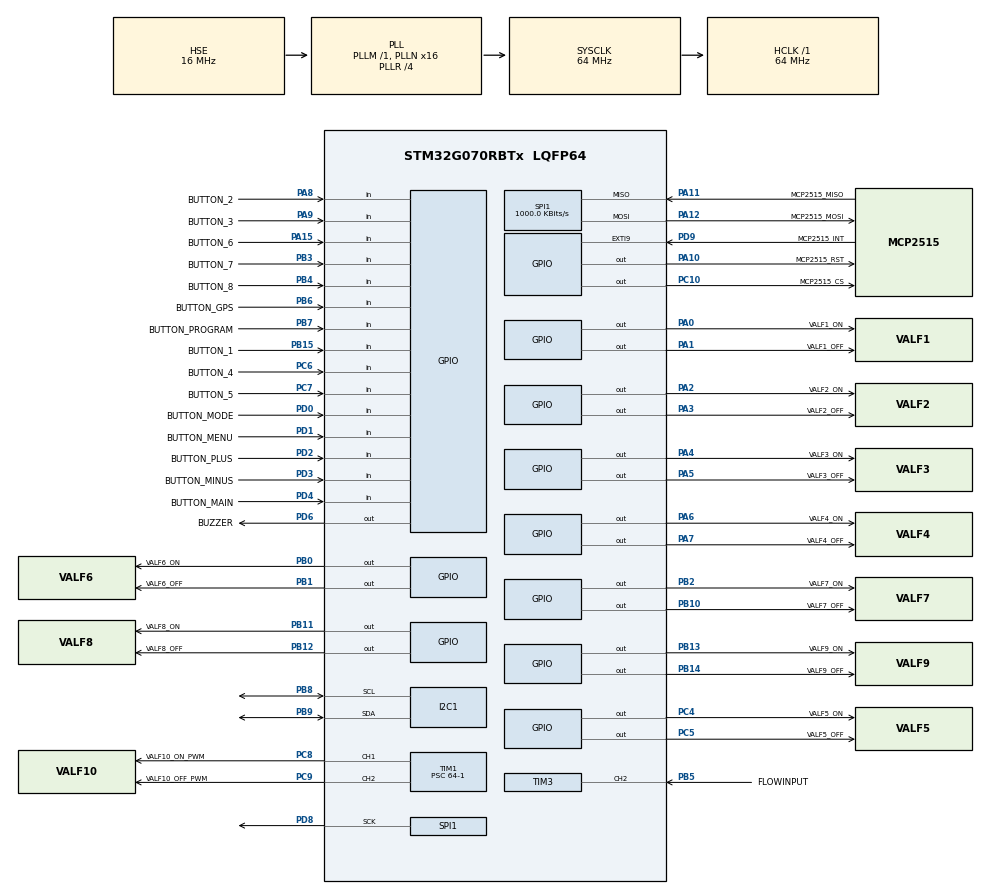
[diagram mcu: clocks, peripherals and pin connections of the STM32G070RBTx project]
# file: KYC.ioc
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Dma.I2C1_TX.0.Direction=DMA_MEMORY_TO_PERIPH
Dma.I2C1_TX.0.EventEnable=DISABLE
Dma.I2C1_TX.0.Instance=DMA1_Channel1
Dma.I2C1_TX.0.MemDataAlignment=DMA_MDATAALIGN_BYTE
Dma.I2C1_TX.0.MemInc=DMA_MINC_ENABLE
Dma.I2C1_TX.0.Mode=DMA_NORMAL
Dma.I2C1_TX.0.PeriphDataAlignment=DMA_PDATAALIGN_BYTE
Dma.I2C1_TX.0.PeriphInc=DMA_PINC_DISABLE
Dma.I2C1_TX.0.Polarity=HAL_DMAMUX_REQ_GEN_RISING
Dma.I2C1_TX.0.Priority=DMA_PRIORITY_LOW
Dma.I2C1_TX.0.RequestNumber=1
Dma.I2C1_TX.0.SignalID=NONE
Dma.I2C1_TX.0.SyncEnable=DISABLE
Dma.I2C1_TX.0.SyncPolarity=HAL_DMAMUX_SYNC_NO_EVENT
Dma.I2C1_TX.0.SyncRequestNumber=1
Dma.I2C1_TX.0.SyncSignalID=NONE
Dma.Request0=I2C1_TX
FREERTOS.Tasks01=defaultTask,0,640,StartDefaultTask,Default,NULL,Dynamic,NULL,NULL
FREERTOS.configTOTAL_HEAP_SIZE=30720
FREERTOS.configUSE_NEWLIB_REENTRANT=1
I2C1.Timing=0x10B17DB5
Mcu.Family=STM32G0
Mcu.Name=STM32G070RBTx
Mcu.Package=LQFP64
NVIC.DMA1_Channel1_IRQn=true\:3\:0\:false\:false\:true\:true\:false\:true\:true
NVIC.I2C1_IRQn=true\:3\:0\:false\:false\:true\:true\:true\:true\:true
NVIC.TIM17_IRQn=true\:3\:0\:false\:false\:true\:true\:true\:true\:true
NVIC.TIM3_IRQn=true\:3\:0\:false\:false\:true\:true\:true\:true\:true
NVIC.TIM7_IRQn=true\:3\:0\:false\:false\:true\:false\:false\:true\:true
NVIC.TimeBase=TIM7_IRQn
NVIC.TimeBaseIP=TIM7
PA0.GPIO_Label=VALF1_ON
PA0.Signal=GPIO_Output
PA1.GPIO_Label=VALF1_OFF
PA1.Signal=GPIO_Output
PA10.GPIO_Label=MCP2515_RST
PA10.PinState=GPIO_PIN_SET
PA10.Signal=GPIO_Output
PA11\ [PA9].GPIO_Label=MCP2515_MISO
PA11\ [PA9].Mode=Full_Duplex_Master
PA11\ [PA9].Signal=SPI1_MISO
PA12\ [PA10].GPIO_Label=MCP2515_MOSI
PA12\ [PA10].Mode=Full_Duplex_Master
PA12\ [PA10].Signal=SPI1_MOSI
PA13.Mode=Serial_Wire
PA13.Signal=SYS_SWDIO
PA14-BOOT0.Mode=Serial_Wire
PA14-BOOT0.Signal=SYS_SWCLK
PA15.GPIO_Label=BUTTON_6
PA15.Signal=GPIO_Input
PA2.GPIO_Label=VALF2_ON
PA2.Signal=GPIO_Output
PA3.GPIO_Label=VALF2_OFF
PA3.Signal=GPIO_Output
PA4.GPIO_Label=VALF3_ON
PA4.Signal=GPIO_Output
PA5.GPIO_Label=VALF3_OFF
PA5.Signal=GPIO_Output
PA6.GPIO_Label=VALF4_ON
PA6.Signal=GPIO_Output
PA7.GPIO_Label=VALF4_OFF
PA7.Signal=GPIO_Output
PA8.GPIO_Label=BUTTON_2
PA8.Signal=GPIO_Input
PA9.GPIO_Label=BUTTON_3
PA9.Signal=GPIO_Input
PB0.GPIO_Label=VALF6_ON
PB0.Signal=GPIO_Output
PB1.GPIO_Label=VALF6_OFF
PB1.Signal=GPIO_Output
PB10.GPIO_Label=VALF7_OFF
PB10.Signal=GPIO_Output
PB11.GPIO_Label=VALF8_ON
PB11.Signal=GPIO_Output
PB12.GPIO_Label=VALF8_OFF
PB12.Signal=GPIO_Output
PB13.GPIO_Label=VALF9_ON
PB13.Signal=GPIO_Output
PB14.GPIO_Label=VALF9_OFF
PB14.Signal=GPIO_Output
PB15.GPIO_Label=BUTTON_1
PB15.Signal=GPIO_Input
PB2.GPIO_Label=VALF7_ON
PB2.Signal=GPIO_Output
PB3.GPIO_Label=BUTTON_7
PB3.Signal=GPIO_Input
PB4.GPIO_Label=BUTTON_8
PB4.Signal=GPIO_Input
PB5.GPIO_Label=FLOWINPUT
PB5.Signal=S_TIM3_CH2
PB6.GPIO_Label=BUTTON_GPS
PB6.Signal=GPIO_Input
PB7.GPIO_Label=BUTTON_PROGRAM
PB7.Signal=GPIO_Input
PB8.Mode=I2C
PB8.Signal=I2C1_SCL
PB9.Mode=I2C
PB9.Signal=I2C1_SDA
PC10.GPIO_Label=MCP2515_CS
PC10.Signal=GPIO_Output
PC4.GPIO_Label=VALF5_ON
PC4.Signal=GPIO_Output
PC5.GPIO_Label=VALF5_OFF
PC5.Signal=GPIO_Output
PC6.GPIO_Label=BUTTON_4
PC6.Signal=GPIO_Input
PC7.GPIO_Label=BUTTON_5
PC7.Signal=GPIO_Input
PC8.GPIO_Label=VALF10_ON_PWM
PC8.Signal=S_TIM1_CH1
PC9.GPIO_Label=VALF10_OFF_PWM
PC9.Signal=S_TIM1_CH2
PD0.GPIO_Label=BUTTON_MODE
PD0.Signal=GPIO_Input
PD1.GPIO_Label=BUTTON_MENU
PD1.Signal=GPIO_Input
PD2.GPIO_Label=BUTTON_PLUS
PD2.Signal=GPIO_Input
PD3.GPIO_Label=BUTTON_MINUS
PD3.Signal=GPIO_Input
PD4.GPIO_Label=BUTTON_MAIN
PD4.Signal=GPIO_Input
PD6.GPIO_Label=BUZZER
PD6.Signal=GPIO_Output
PD8.Mode=Full_Duplex_Master
PD8.Signal=SPI1_SCK
PD9.GPIO_Label=MCP2515_INT
PD9.Signal=GPXTI9
PF0-OSC_IN\ (PF0).Mode=HSE-External-Oscillator
PF0-OSC_IN\ (PF0).Signal=RCC_OSC_IN
PF1-OSC_OUT\ (PF1).Mode=HSE-External-Oscillator
PF1-OSC_OUT\ (PF1).Signal=RCC_OSC_OUT
ProjectManager.HeapSize=0x200
ProjectManager.StackSize=0x400
ProjectManager.TargetToolchain=CMake
RCC.ADCFreq_Value=64000000
RCC.AHBFreq_Value=64000000
RCC.CortexFreq_Value=64000000
RCC.EXTERNAL_CLOCK_VALUE=48000
RCC.HCLKFreq_Value=64000000
RCC.HSE_VALUE=16000000
RCC.HSI_VALUE=16000000
RCC.LSE_VALUE=32768
RCC.PLLN=16
RCC.PLLR=RCC_PLLR_DIV4
RCC.PLLSourceVirtual=RCC_PLLSOURCE_HSE
RCC.SYSCLKFreq_VALUE=64000000
RCC.SYSCLKSource=RCC_SYSCLKSOURCE_PLLCLK
RCC.VCOOutputFreq_Value=256000000
SH.S_TIM1_CH1.0=TIM1_CH1,PWM Generation1 CH1
SH.S_TIM1_CH2.0=TIM1_CH2,PWM Generation2 CH2
SH.S_TIM3_CH2.0=TIM3_CH2,Input_Capture2_from_TI2
SPI1.BaudRatePrescaler=SPI_BAUDRATEPRESCALER_64
SPI1.CalculateBaudRate=1000.0 KBits/s
SPI1.DataSize=SPI_DATASIZE_8BIT
SPI1.Direction=SPI_DIRECTION_2LINES
SPI1.Mode=SPI_MODE_MASTER
SPI1.NSSPMode=SPI_NSS_PULSE_DISABLE
SPI1.VirtualType=VM_MASTER
TIM1.Channel-PWM\ Generation1\ CH1=TIM_CHANNEL_1
TIM1.Channel-PWM\ Generation2\ CH2=TIM_CHANNEL_2
TIM1.Period=100-1
TIM1.Prescaler=64-1
TIM16.Prescaler=64-1
TIM17.Period=1000-1
TIM17.Prescaler=64-1
TIM3.Channel-Input_Capture2_from_TI2=TIM_CHANNEL_2
TIM3.ICFilter_CH2=4
TIM3.ICPolarity_CH2=TIM_INPUTCHANNELPOLARITY_FALLING
TIM3.Prescaler=64-1
VP_FREERTOS_VS_CMSIS_V1.Mode=CMSIS_V1
VP_SYS_VS_tim7.Mode=TIM7
VP_TIM16_VS_ClockSourceINT.Mode=Enable_Timer
VP_TIM17_VS_ClockSourceINT.Mode=Enable_Timer
VP_TIM1_VS_ClockSourceINT.Mode=Internal
board=custom

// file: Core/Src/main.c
/* USER CODE BEGIN Header */
/**
  ******************************************************************************
  * @file           : main.c
  * @brief          : Main program body
  ******************************************************************************
  * @attention
  *
  * Copyright (c) 2025 STMicroelectronics.
  * All rights reserved.
  *
  * This software is licensed under terms that can be found in the LICENSE file
  * in the root directory of this software component.
  * If no LICENSE file comes with this software, it is provided AS-IS.
  *
  ******************************************************************************
  */
/* USER CODE END Header */
#include "main.h"
#include "cmsis_os.h"
#include "dma.h"
#include "i2c.h"
#include "spi.h"
#include "tim.h"
#include "gpio.h"

void SystemClock_Config(void);
void MX_FREERTOS_Init(void);

int main(void)
{

  /* MCU Configuration--------------------------------------------------------*/

  /* Reset of all peripherals, Initializes the Flash interface and the Systick. */
  HAL_Init();

  /* Configure the system clock */
  SystemClock_Config();

  /* Initialize all configured peripherals */
  MX_GPIO_Init();
  MX_DMA_Init();
  MX_I2C1_Init();
  MX_TIM1_Init();
  MX_TIM3_Init();
  MX_TIM17_Init();
  MX_TIM16_Init();
  MX_SPI1_Init();

  /* Call init function for freertos objects (in cmsis_os2.c) */
  MX_FREERTOS_Init();

  /* Start scheduler */
  osKernelStart();

  /* We should never get here as control is now taken by the scheduler */

  /* Infinite loop */
  while (1)
  {

  }
}

void SystemClock_Config(void)
{
  RCC_OscInitTypeDef RCC_OscInitStruct = {0};
  RCC_ClkInitTypeDef RCC_ClkInitStruct = {0};

  /** Configure the main internal regulator output voltage
  */
  HAL_PWREx_ControlVoltageScaling(PWR_REGULATOR_VOLTAGE_SCALE1);

  /** Initializes the RCC Oscillators according to the specified parameters
  * in the RCC_OscInitTypeDef structure.
  */
  RCC_OscInitStruct.OscillatorType = RCC_OSCILLATORTYPE_HSE;
  RCC_OscInitStruct.HSEState = RCC_HSE_ON;
  RCC_OscInitStruct.PLL.PLLState = RCC_PLL_ON;
  RCC_OscInitStruct.PLL.PLLSource = RCC_PLLSOURCE_HSE;
  RCC_OscInitStruct.PLL.PLLM = RCC_PLLM_DIV1;
  RCC_OscInitStruct.PLL.PLLN = 16;
  RCC_OscInitStruct.PLL.PLLP = RCC_PLLP_DIV2;
  RCC_OscInitStruct.PLL.PLLR = RCC_PLLR_DIV4;
  if (HAL_RCC_OscConfig(&RCC_OscInitStruct) != HAL_OK)
  {
    Error_Handler();
  }

  /** Initializes the CPU, AHB and APB buses clocks
  */
  RCC_ClkInitStruct.ClockType = RCC_CLOCKTYPE_HCLK|RCC_CLOCKTYPE_SYSCLK
                              |RCC_CLOCKTYPE_PCLK1;
  RCC_ClkInitStruct.SYSCLKSource = RCC_SYSCLKSOURCE_PLLCLK;
  RCC_ClkInitStruct.AHBCLKDivider = RCC_SYSCLK_DIV1;
  RCC_ClkInitStruct.APB1CLKDivider = RCC_HCLK_DIV1;

  if (HAL_RCC_ClockConfig(&RCC_ClkInitStruct, FLASH_LATENCY_2) != HAL_OK)
  {
    Error_Handler();
  }
}

void HAL_TIM_PeriodElapsedCallback(TIM_HandleTypeDef *htim)
{
  if (htim->Instance == TIM7)
  {
    HAL_IncTick();
  }
}

void Error_Handler(void)
{
  __disable_irq();
  while (1)
  {
  }
}

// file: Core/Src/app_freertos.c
/* USER CODE BEGIN Header */
/**
  ******************************************************************************
  * File Name          : app_freertos.c
  * Description        : Code for freertos applications
  ******************************************************************************
  * @attention
  *
  * Copyright (c) 2025 STMicroelectronics.
  * All rights reserved.
  *
  * This software is licensed under terms that can be found in the LICENSE file
  * in the root directory of this software component.
  * If no LICENSE file comes with this software, it is provided AS-IS.
  *
  ******************************************************************************
  */
/* USER CODE END Header */

#include "FreeRTOS.h"
#include "task.h"
#include "main.h"
#include "cmsis_os.h"

/* USER CODE BEGIN Includes */
#include "app.h"
/* USER CODE END Includes */

osThreadId defaultTaskHandle;

void StartDefaultTask(void const * argument);

void MX_FREERTOS_Init(void); /* (MISRA C 2004 rule 8.1) */

void MX_FREERTOS_Init(void) {

  /* Create the thread(s) */
  /* definition and creation of defaultTask */
  osThreadDef(defaultTask, StartDefaultTask, osPriorityNormal, 0, 640);
  defaultTaskHandle = osThreadCreate(osThread(defaultTask), NULL);

}

void StartDefaultTask(void const * argument)
{
  for(;;)
  {
    osDelay(1);
  }
}
